# CM_GFX register map
Vendor: Texas Instruments
Peripheral module from a debugger description file (folder am437x).
Registers are 32-bit, access per field, no defined reset value unless marked. A register's access mark holds for its fields unless they carry their own. Offsets are as the file gives them; lines under a group give offsets from that group; [hi:lo] are bit positions; {n}, {i} and the like mark numbered series; 'fields as' and 'values as' point back to an identical list; <NAME> marks a mode.

## CM_GFX
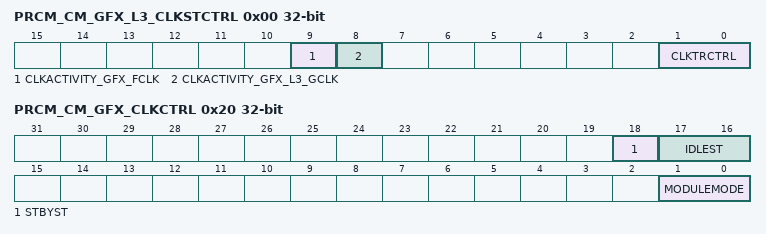
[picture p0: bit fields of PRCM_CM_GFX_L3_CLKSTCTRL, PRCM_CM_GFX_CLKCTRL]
0x00 PRCM_CM_GFX_L3_CLKSTCTRL — This register enables the domain power state transition. It controls the SW supervised clock domain state transition between ON-ACTIVE and ON-INACTIVE states. It also hold one status bit per clock input of the domain.
  [9] CLKACTIVITY_GFX_FCLK ro — This field indicates the state of the GFX_GCLK clock in the domain.
    1=en_2_0x1 (Corresponding clock is active); 0=en_1_0x0 (Corresponding clock is gated)
  [8] CLKACTIVITY_GFX_L3_GCLK ro — This field indicates the state of the GFX_L3_GCLK clock in the domain.
    values as CLKACTIVITY_GFX_FCLK
  [1:0] CLKTRCTRL rw — Controls the clock state transition of the GFX clock domain in GFX power domain.
    3=en_4_0x3 (Reserved); 2=en_3_0x2 (SW_WKUP: Start a software forced wake-up transition on the domain.); 1=en_2_0x1 (SW_SLEEP: Start a software forced sleep transition on the domain.); 0=en_1_0x0 (NO_SLEEP: Sleep transition cannot be initiated. Wakeup transition may however occur.)
0x20 PRCM_CM_GFX_CLKCTRL — This register manages the GFX clocks.
  [18] STBYST ro — Module standby status.
    1=en_2_0x1 (Module is in standby); 0=en_1_0x0 (Module is functional (not in standby))
  [17:16] IDLEST ro — Module idle status.
    3=en_4_0x3 (Module is disabled and cannot be accessed); 2=en_3_0x2 (Module is in Idle mode (only OCP part). It is functional if using separate functional clock); 1=en_2_0x1 (Module is performing transition: wakeup, or sleep, or sleep abortion); 0=en_1_0x0 (Module is fully functional, including OCP)
  [1:0] MODULEMODE rw — Control the way mandatory clocks are managed.
    3=en_4_0x3 (Reserved); 2=en_3_0x2 (Module is explicitly enabled. Interface clock (if not used for functions) may be gated according to the clock domain state. Functional clocks are guarantied to stay present. As long as in this configuration, power domain sleep transition cannot happen.); 1=en_2_0x1 (Reserved); 0=en_1_0x0 (Module is disable by SW. Any OCP access to module results in an error, except if resulting from a module wakeup (asynchronous wakeup).)
